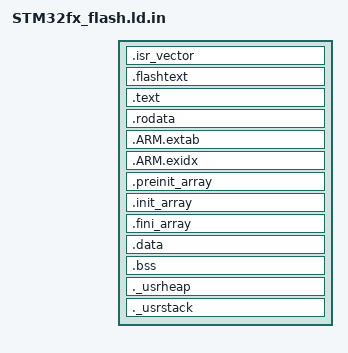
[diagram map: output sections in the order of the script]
INCLUDE ${CMAKE_CURRENT_BINARY_DIR}/${TARGET}_stm32${STM32_SERIES_LOWER}_memory.ld

/* Entry Point */
ENTRY(Reset_Handler)

/* Generate a link error if heap and stack don't fit into RAM */
_Min_Heap_Size = ${STM32_MIN_HEAP_SIZE};      /* required amount of heap  */
_Min_Stack_Size = ${STM32_MIN_STACK_SIZE}; /* required amount of stack */

SECTIONS
{
    /* for Cortex devices, the beginning of the startup code is stored in the .isr_vector section, which goes to FLASH */
    .isr_vector :
    {
        . = ALIGN(4);
        KEEP(*(.isr_vector))            /* Startup code */
        . = ALIGN(4);
    } >FLASH
 
    /* for some STRx devices, the beginning of the startup code is stored in the .flashtext section, which goes to FLASH */
    .flashtext :
    {
        . = ALIGN(4);
        *(.flashtext)            /* Startup code */
        . = ALIGN(4);
    } >FLASH
    
    /* the program code is stored in the .text section, which goes to Flash */
    .text :
    {
        . = ALIGN(4);

        *(.text)
        *(.text*)

        KEEP(*(.init))
        KEEP(*(.fini))

        /* .ctors */
        *crtbegin.o(.ctors)
        *crtbegin?.o(.ctors)
        *(EXCLUDE_FILE(*crtend?.o *crtend.o) .ctors)
        *(SORT(.ctors.*))
        *(.ctors)

        /* .dtors */
        *crtbegin.o(.dtors)
        *crtbegin?.o(.dtors)
        *(EXCLUDE_FILE(*crtend?.o *crtend.o) .dtors)
        *(SORT(.dtors.*))
        *(.dtors)

        KEEP(*(.eh_frame*))
    } >FLASH

    .rodata :
    {
        *(.rodata*)
    } >FLASH
    
    .ARM.extab : 
    {
        *(.ARM.extab* .gnu.linkonce.armextab.*)
    } > FLASH

    .ARM.exidx :
    {
        __exidx_start = ABSOLUTE(.);
        *(.ARM.exidx* .gnu.linkonce.armexidx.*)
        __exidx_end = ABSOLUTE(.);
    } > FLASH

    .preinit_array     :
    {
        PROVIDE_HIDDEN (__preinit_array_start = ABSOLUTE(.));
        KEEP (*(.preinit_array*))
        PROVIDE_HIDDEN (__preinit_array_end = ABSOLUTE(.));
    } >FLASH

    .init_array :
    {
        PROVIDE_HIDDEN (__init_array_start = ABSOLUTE(.));
        KEEP (*(SORT(.init_array.*)))
        KEEP (*(.init_array*))
        PROVIDE_HIDDEN (__init_array_end = ABSOLUTE(.));
    } >FLASH

    .fini_array :
    {
        PROVIDE_HIDDEN (__fini_array_start = ABSOLUTE(.));
        KEEP (*(SORT(.fini_array.*)))
        KEEP (*(.fini_array*))
        PROVIDE_HIDDEN (__fini_array_end = ABSOLUTE(.));
    } >FLASH
  
    __etext = .;
    _sidata = __etext;

     /* This is the initialized data section
    The program executes knowing that the data is in the RAM
    but the loader puts the initial values in the FLASH (inidata).
    It is one task of the startup to copy the initial values from FLASH to RAM. */
    .data  : AT ( _sidata )
    {
        . = ALIGN(4);
        /* This is used by the startup in order to initialize the .data section */
        _sdata = ABSOLUTE(.);

        *(vtable)
        *(.data)
        *(.data*)
        
        /* This is used by the startup in order to initialize the .data section */
        _edata = ABSOLUTE(.);
    } >RAM

    /* This is the uninitialized data section */
    .bss :
    {
        . = ALIGN(4);
        /* This is used by the startup in order to initialize the .bss section */
        _sbss = ABSOLUTE(.);
        
        *(.bss*)
        *(COMMON)
        
        . = ALIGN(4);
        /* This is used by the startup in order to initialize the .bss section */
        _ebss = ABSOLUTE(.);
    } >RAM  AT>RAM

    INCLUDE ${CMAKE_CURRENT_BINARY_DIR}/${TARGET}_stm32${STM32_SERIES_LOWER}_sections.ld
    
    ._usrheap (COPY): 
    {
        . = ALIGN(4);
        __end__ = .;
        PROVIDE(end = .);
        PROVIDE(_end = .);
	PROVIDE(__HeapStart = .);
        . += _Min_Heap_Size;
        PROVIDE(__HeapLimit = .);
    } >RAM
    
    /* This is the user stack section 
    This is just to check that there is enough RAM left for the User mode stack
    It should generate an error if it's full.
     */
    ._usrstack (ORIGIN(RAM) + LENGTH(RAM) - _Min_Stack_Size) (COPY): 
    {
        . += _Min_Stack_Size;
	_estack = .;
    } >RAM

    ASSERT(ADDR(._usrheap) + SIZEOF(._usrheap) <= ADDR(._usrstack), "region RAM overflowed with stack")
}
